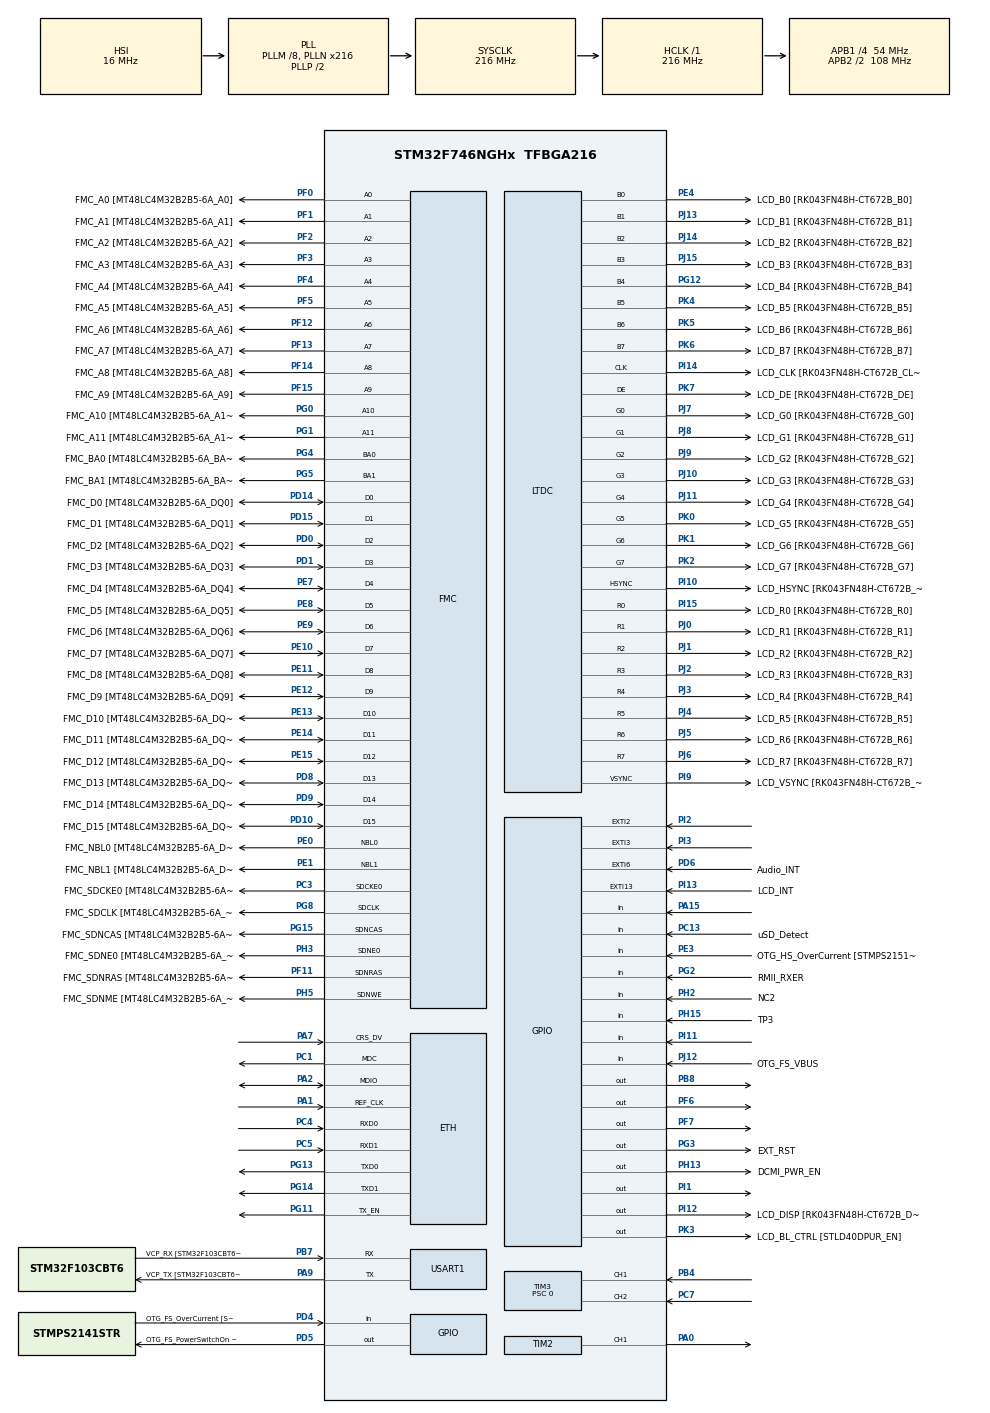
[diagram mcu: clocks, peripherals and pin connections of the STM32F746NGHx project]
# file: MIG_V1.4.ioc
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ETH.MediaInterface=HAL_ETH_RMII_MODE
FMC.CASLatency1=FMC_SDRAM_CAS_LATENCY_3
FMC.ExitSelfRefreshDelay1=7
FMC.LoadToActiveDelay1=4
FMC.RCDDelay1=3
FMC.RPDelay1=3
FMC.RPDelay2=3
FMC.ReadBurst1=FMC_SDRAM_RBURST_ENABLE
FMC.ReadBurst2=FMC_SDRAM_RBURST_ENABLE
FMC.RowCycleDelay1=7
FMC.RowCycleDelay2=7
FMC.SDClockPeriod1=FMC_SDRAM_CLOCK_PERIOD_2
FMC.SelfRefreshTime1=3
FMC.WriteRecoveryTime1=3
LWIP.BSP.number=1
LWIP.GATEWAY_ADDRESS=192.168.001.100
LWIP.IP_ADDRESS=172.024.001.001
LWIP.LWIP_DHCP=0
LWIP.LWIP_HTTPD=1
LWIP.LWIP_HTTPD_MAX_CGI_PARAMETERS=30
LWIP.LWIP_HTTPD_MAX_REQUEST_URI_LEN=500
LWIP.LWIP_HTTPD_POST_MAX_RESPONSE_URI_LEN=500
LWIP.LWIP_HTTPD_SSI_INCLUDE_TAG=0
LWIP.NETMASK_ADDRESS=255.255.000.000
LWIP.Version=v2.1.2_Cube
LWIP0.BSP.STBoard=false
LWIP0.BSP.api=BSP_COMPONENT_DRIVER
LWIP0.BSP.component=LAN8742
LWIP0.BSP.instance=LAN8742
LWIP0.BSP.name=Driver_PHY
LWIP0.BSP.semaphore=S_LAN8742
LWIP0.BSP.solution=LAN8742
Mcu.Family=STM32F7
Mcu.Name=STM32F746NGHx
Mcu.Package=TFBGA216
NVIC.PriorityGroup=NVIC_PRIORITYGROUP_4
NVIC.TIM3_IRQn=true\:0\:0\:false\:false\:true\:true\:true\:true
PA0/WKUP.Signal=S_TIM2_CH1_ETR
PA1.GPIO_Mode=GPIO_MODE_AF_PP
PA1.GPIO_PuPd=GPIO_NOPULL
PA1.GPIO_Speed=GPIO_SPEED_FREQ_VERY_HIGH
PA1.Mode=RMII
PA1.Signal=ETH_REF_CLK
PA10.GPIO_Label=OTG_FS_ID
PA10.Signal=USB_OTG_FS_ID
PA11.GPIO_Label=OTG_FS_N
PA11.Signal=USB_OTG_FS_DM
PA12.GPIO_Label=OTG_FS_P
PA12.Signal=USB_OTG_FS_DP
PA13.GPIO_Label=SWDIO
PA13.Signal=SYS_JTMS-SWDIO
PA14.GPIO_Label=SWCLK
PA14.Signal=SYS_JTCK-SWCLK
PA15.GPIO_PuPd=GPIO_PULLUP
PA15.Signal=GPIO_Input
PA2.GPIO_Mode=GPIO_MODE_AF_PP
PA2.GPIO_PuPd=GPIO_NOPULL
PA2.GPIO_Speed=GPIO_SPEED_FREQ_VERY_HIGH
PA2.Mode=RMII
PA2.Signal=ETH_MDIO
PA3.GPIO_Label=ULPI_D0 [USB3320C-EZK_D0]
PA3.Signal=USB_OTG_HS_ULPI_D0
PA4.GPIO_Label=DCMI_HSYNC
PA4.Signal=DCMI_HSYNC
PA5.GPIO_Label=ULPI_CLK [USB3320C-EZK_CLKOUT]
PA5.Signal=USB_OTG_HS_ULPI_CK
PA6.Signal=DCMI_PIXCLK
PA7.GPIO_Mode=GPIO_MODE_AF_PP
PA7.GPIO_PuPd=GPIO_NOPULL
PA7.GPIO_Speed=GPIO_SPEED_FREQ_VERY_HIGH
PA7.Mode=RMII
PA7.Signal=ETH_CRS_DV
PA9.GPIO_Label=VCP_TX [STM32F103CBT6_PA3]
PA9.GPIO_Mode=GPIO_MODE_AF_PP
PA9.GPIO_PuPd=GPIO_NOPULL
PA9.GPIO_Speed=GPIO_SPEED_FREQ_LOW
PA9.Mode=Asynchronous
PA9.Signal=USART1_TX
PB0.GPIO_Label=ULPI_D1 [USB3320C-EZK_D1]
PB0.Signal=USB_OTG_HS_ULPI_D1
PB1.GPIO_Label=ULPI_D2 [USB3320C-EZK_D2]
PB1.Signal=USB_OTG_HS_ULPI_D2
PB10.GPIO_Label=ULPI_D3 [USB3320C-EZK_D3]
PB10.Signal=USB_OTG_HS_ULPI_D3
PB11.GPIO_Label=ULPI_D4 [USB3320C-EZK_D4]
PB11.Signal=USB_OTG_HS_ULPI_D4
PB12.GPIO_Label=ULPI_D5 [USB3320C-EZK_D5]
PB12.Signal=USB_OTG_HS_ULPI_D5
PB13.GPIO_Label=ULPI_D6 [USB3320C-EZK_D6]
PB13.Signal=USB_OTG_HS_ULPI_D6
PB2.Signal=QUADSPI_CLK
PB3.GPIO_Label=SWO
PB3.Signal=SYS_JTDO-SWO
PB4.Signal=S_TIM3_CH1
PB5.GPIO_Label=ULPI_D7 [USB3320C-EZK_D7]
PB5.Signal=USB_OTG_HS_ULPI_D7
PB6.GPIO_Label=QSPI_NCS [N25Q128A13EF840E_S]
PB6.Signal=QUADSPI_BK1_NCS
PB7.GPIO_Label=VCP_RX [STM32F103CBT6_PA2]
PB7.GPIO_Mode=GPIO_MODE_AF_PP
PB7.GPIO_PuPd=GPIO_NOPULL
PB7.GPIO_Speed=GPIO_SPEED_FREQ_LOW
PB7.Mode=Asynchronous
PB7.Signal=USART1_RX
PB8.Signal=GPIO_Output
PC0.GPIO_Label=ULPI_STP [USB3320C-EZK_STP]
PC0.Signal=USB_OTG_HS_ULPI_STP
PC1.GPIO_Mode=GPIO_MODE_AF_PP
PC1.GPIO_PuPd=GPIO_NOPULL
PC1.GPIO_Speed=GPIO_SPEED_FREQ_VERY_HIGH
PC1.Mode=RMII
PC1.Signal=ETH_MDC
PC10.GPIO_Label=SDMMC_D2
PC10.Signal=SDMMC1_D2
PC11.GPIO_Label=SDMMC_D3
PC11.Signal=SDMMC1_D3
PC12.GPIO_Label=SDMMC_CK
PC12.Signal=SDMMC1_CK
PC13.GPIO_Label=uSD_Detect
PC13.Signal=GPIO_Input
PC14/OSC32_IN.GPIO_Label=RCC_OSC32_IN
PC14/OSC32_IN.Mode=LSE-External-Oscillator
PC14/OSC32_IN.Signal=RCC_OSC32_IN
PC15/OSC32_OUT.GPIO_Label=RCC_OSC32_OUT
PC15/OSC32_OUT.Mode=LSE-External-Oscillator
PC15/OSC32_OUT.Signal=RCC_OSC32_OUT
PC2.GPIO_Label=ULPI_DIR [USB3320C-EZK_DIR]
PC2.Signal=USB_OTG_HS_ULPI_DIR
PC3.GPIO_Label=FMC_SDCKE0 [MT48LC4M32B2B5-6A_CKE]
PC3.Mode=SdramChipSelect1_1
PC3.Signal=FMC_SDCKE0
PC4.GPIO_Mode=GPIO_MODE_AF_PP
PC4.GPIO_PuPd=GPIO_NOPULL
PC4.GPIO_Speed=GPIO_SPEED_FREQ_VERY_HIGH
PC4.Mode=RMII
PC4.Signal=ETH_RXD0
PC5.GPIO_Mode=GPIO_MODE_AF_PP
PC5.GPIO_PuPd=GPIO_NOPULL
PC5.GPIO_Speed=GPIO_SPEED_FREQ_VERY_HIGH
PC5.Mode=RMII
PC5.Signal=ETH_RXD1
PC7.Signal=S_TIM3_CH2
PC8.Signal=SDMMC1_D0
PC9.Signal=SDMMC1_D1
PD0.GPIO_Label=FMC_D2 [MT48LC4M32B2B5-6A_DQ2]
PD0.Signal=FMC_D2_DA2
PD1.GPIO_Label=FMC_D3 [MT48LC4M32B2B5-6A_DQ3]
PD1.Signal=FMC_D3_DA3
PD10.GPIO_Label=FMC_D15 [MT48LC4M32B2B5-6A_DQ15]
PD10.Signal=FMC_D15_DA15
PD11.GPIO_Label=QSPI_D0 [N25Q128A13EF840E_DQ0]
PD11.Signal=QUADSPI_BK1_IO0
PD12.GPIO_Label=QSPI_D1 [N25Q128A13EF840E_DQ1]
PD12.Signal=QUADSPI_BK1_IO1
PD13.GPIO_Label=QSPI_D3 [N25Q128A13EF840E_DQ3]
PD13.Signal=QUADSPI_BK1_IO3
PD14.GPIO_Label=FMC_D0 [MT48LC4M32B2B5-6A_DQ0]
PD14.Signal=FMC_D0_DA0
PD15.GPIO_Label=FMC_D1 [MT48LC4M32B2B5-6A_DQ1]
PD15.Signal=FMC_D1_DA1
PD2.GPIO_Label=SDMMC_D0
PD2.Signal=SDMMC1_CMD
PD3.GPIO_Label=DCMI_D5
PD3.Signal=DCMI_D5
PD4.GPIO_Label=OTG_FS_OverCurrent [STMPS2141STR_Fault]
PD4.Signal=GPIO_Input
PD5.GPIO_Label=OTG_FS_PowerSwitchOn [STMPS2141STR_EN]
PD5.PinState=GPIO_PIN_SET
PD5.Signal=GPIO_Output
PD6.GPIO_Label=Audio_INT
PD6.GPIO_ModeDefaultEXTI=GPIO_MODE_EVT_RISING
PD6.Signal=GPXTI6
PD7.GPIO_Label=SPDIF_RX0 [74LVC1G04SE_4]
PD7.Signal=SPDIFRX_IN0
PD8.GPIO_Label=FMC_D13 [MT48LC4M32B2B5-6A_DQ13]
PD8.Signal=FMC_D13_DA13
PD9.GPIO_Label=FMC_D14 [MT48LC4M32B2B5-6A_DQ14]
PD9.Signal=FMC_D14_DA14
PE0.GPIO_Label=FMC_NBL0 [MT48LC4M32B2B5-6A_DQM0]
PE0.Signal=FMC_NBL0
PE1.GPIO_Label=FMC_NBL1 [MT48LC4M32B2B5-6A_DQM1]
PE1.Signal=FMC_NBL1
PE10.GPIO_Label=FMC_D7 [MT48LC4M32B2B5-6A_DQ7]
PE10.Signal=FMC_D7_DA7
PE11.GPIO_Label=FMC_D8 [MT48LC4M32B2B5-6A_DQ8]
PE11.Signal=FMC_D8_DA8
PE12.GPIO_Label=FMC_D9 [MT48LC4M32B2B5-6A_DQ9]
PE12.Signal=FMC_D9_DA9
PE13.GPIO_Label=FMC_D10 [MT48LC4M32B2B5-6A_DQ10]
PE13.Signal=FMC_D10_DA10
PE14.GPIO_Label=FMC_D11 [MT48LC4M32B2B5-6A_DQ11]
PE14.Signal=FMC_D11_DA11
PE15.GPIO_Label=FMC_D12 [MT48LC4M32B2B5-6A_DQ12]
PE15.Signal=FMC_D12_DA12
PE2.GPIO_Label=QSPI_D2 [N25Q128A13EF840E_DQ2]
PE2.Signal=QUADSPI_BK1_IO2
PE3.GPIO_Label=OTG_HS_OverCurrent [STMPS2151STR_FAULT]
PE3.Signal=GPIO_Input
PE4.GPIO_Label=LCD_B0 [RK043FN48H-CT672B_B0]
PE4.Mode=RGB888
PE4.Signal=LTDC_B0
PE5.GPIO_Label=DCMI_D6
PE5.Signal=DCMI_D6
PE6.GPIO_Label=DCMI_D7
PE6.Signal=DCMI_D7
PE7.GPIO_Label=FMC_D4 [MT48LC4M32B2B5-6A_DQ4]
PE7.Signal=FMC_D4_DA4
PE8.GPIO_Label=FMC_D5 [MT48LC4M32B2B5-6A_DQ5]
PE8.Signal=FMC_D5_DA5
PE9.GPIO_Label=FMC_D6 [MT48LC4M32B2B5-6A_DQ6]
PE9.Signal=FMC_D6_DA6
PF0.GPIO_Label=FMC_A0 [MT48LC4M32B2B5-6A_A0]
PF0.Signal=FMC_A0
PF1.GPIO_Label=FMC_A1 [MT48LC4M32B2B5-6A_A1]
PF1.Signal=FMC_A1
PF11.GPIO_Label=FMC_SDNRAS [MT48LC4M32B2B5-6A_RAS]
PF11.Signal=FMC_SDNRAS
PF12.GPIO_Label=FMC_A6 [MT48LC4M32B2B5-6A_A6]
PF12.Signal=FMC_A6
PF13.GPIO_Label=FMC_A7 [MT48LC4M32B2B5-6A_A7]
PF13.Signal=FMC_A7
PF14.GPIO_Label=FMC_A8 [MT48LC4M32B2B5-6A_A8]
PF14.Signal=FMC_A8
PF15.GPIO_Label=FMC_A9 [MT48LC4M32B2B5-6A_A9]
PF15.Signal=FMC_A9
PF2.GPIO_Label=FMC_A2 [MT48LC4M32B2B5-6A_A2]
PF2.Signal=FMC_A2
PF3.GPIO_Label=FMC_A3 [MT48LC4M32B2B5-6A_A3]
PF3.Signal=FMC_A3
PF4.GPIO_Label=FMC_A4 [MT48LC4M32B2B5-6A_A4]
PF4.Signal=FMC_A4
PF5.GPIO_Label=FMC_A5 [MT48LC4M32B2B5-6A_A5]
PF5.Signal=FMC_A5
PF6.Signal=GPIO_Output
PF7.Signal=GPIO_Output
PG0.GPIO_Label=FMC_A10 [MT48LC4M32B2B5-6A_A10]
PG0.Signal=FMC_A10
PG1.GPIO_Label=FMC_A11 [MT48LC4M32B2B5-6A_A11]
PG1.Signal=FMC_A11
PG10.GPIO_Label=SAI2_SDB [WM8994ECS/R_ADCDAT1]
PG10.Signal=SAI2_SD_B
PG11.GPIO_Mode=GPIO_MODE_AF_PP
PG11.GPIO_PuPd=GPIO_NOPULL
PG11.GPIO_Speed=GPIO_SPEED_FREQ_VERY_HIGH
PG11.Mode=RMII
PG11.Signal=ETH_TX_EN
PG12.GPIO_Label=LCD_B4 [RK043FN48H-CT672B_B4]
PG12.Mode=RGB888
PG12.Signal=LTDC_B4
PG13.GPIO_Mode=GPIO_MODE_AF_PP
PG13.GPIO_PuPd=GPIO_NOPULL
PG13.GPIO_Speed=GPIO_SPEED_FREQ_VERY_HIGH
PG13.Mode=RMII
PG13.Signal=ETH_TXD0
PG14.GPIO_Mode=GPIO_MODE_AF_PP
PG14.GPIO_PuPd=GPIO_NOPULL
PG14.GPIO_Speed=GPIO_SPEED_FREQ_VERY_HIGH
PG14.Mode=RMII
PG14.Signal=ETH_TXD1
PG15.GPIO_Label=FMC_SDNCAS [MT48LC4M32B2B5-6A_CAS]
PG15.Signal=FMC_SDNCAS
PG2.GPIO_Label=RMII_RXER
PG2.Signal=GPIO_Input
PG3.GPIO_Label=EXT_RST
PG3.Signal=GPIO_Output
PG4.GPIO_Label=FMC_BA0 [MT48LC4M32B2B5-6A_BA0]
PG4.Signal=FMC_A14_BA0
PG5.GPIO_Label=FMC_BA1 [MT48LC4M32B2B5-6A_BA1]
PG5.Signal=FMC_A15_BA1
PG8.GPIO_Label=FMC_SDCLK [MT48LC4M32B2B5-6A_CLK]
PG8.Signal=FMC_SDCLK
PG9.GPIO_Label=DCMI_VSYNC
PG9.Signal=DCMI_VSYNC
PH0/OSC_IN.GPIO_Label=OSC_25M [NZ2520SB-25.00M_OUT]
PH0/OSC_IN.Signal=RCC_OSC_IN
PH1/OSC_OUT.Signal=RCC_OSC_OUT
PH10.GPIO_Label=DCMI_D1
PH10.Signal=DCMI_D1
PH11.GPIO_Label=DCMI_D2
PH11.Signal=DCMI_D2
PH12.GPIO_Label=DCMI_D3
PH12.Signal=DCMI_D3
PH13.GPIO_Label=DCMI_PWR_EN
PH13.Signal=GPIO_Output
PH14.GPIO_Label=DCMI_D4
PH14.Signal=DCMI_D4
PH15.GPIO_Label=TP3
PH15.Signal=GPIO_Input
PH2.GPIO_Label=NC2
PH2.Signal=GPIO_Input
PH3.GPIO_Label=FMC_SDNE0 [MT48LC4M32B2B5-6A_CS]
PH3.Mode=SdramChipSelect1_1
PH3.Signal=FMC_SDNE0
PH4.GPIO_Label=ULPI_NXT [USB3320C-EZK_NXT]
PH4.Signal=USB_OTG_HS_ULPI_NXT
PH5.GPIO_Label=FMC_SDNME [MT48LC4M32B2B5-6A_WE]
PH5.Signal=FMC_SDNWE
PH7.GPIO_Label=LCD_SCL [RK043FN48H-CT672B_SCL]
PH7.Signal=I2C3_SCL
PH8.GPIO_Label=LCD_SDA [RK043FN48H-CT672B_SDA]
PH8.Signal=I2C3_SDA
PH9.GPIO_Label=DCMI_D0
PH9.Signal=DCMI_D0
PI1.Signal=GPIO_Output
PI10.GPIO_Label=LCD_HSYNC [RK043FN48H-CT672B_HSYNC]
PI10.Mode=RGB888
PI10.Signal=LTDC_HSYNC
PI11.GPIO_PuPd=GPIO_PULLUP
PI11.Signal=GPIO_Input
PI12.GPIO_Label=LCD_DISP [RK043FN48H-CT672B_DISP] 
PI12.Signal=GPIO_Output
PI13.GPIO_Label=LCD_INT
PI13.GPIO_ModeDefaultEXTI=GPIO_MODE_EVT_RISING
PI13.Signal=GPXTI13
PI14.GPIO_Label=LCD_CLK [RK043FN48H-CT672B_CLK]
PI14.Mode=RGB888
PI14.Signal=LTDC_CLK
PI15.GPIO_Label=LCD_R0 [RK043FN48H-CT672B_R0]
PI15.Mode=RGB888
PI15.Signal=LTDC_R0
PI2.Signal=GPXTI2
PI3.GPIO_ModeDefaultEXTI=GPIO_MODE_IT_RISING
PI3.Signal=GPXTI3
PI4.GPIO_Label=SAI2_MCLKA [WM8994ECS/R_MCLK1]
PI4.Signal=SAI2_MCLK_A
PI5.GPIO_Label=SAI2_SCKA [WM8994ECS/R_BCLK1]
PI5.Signal=SAI2_SCK_A
PI6.GPIO_Label=SAI2_SDA [WM8994ECS/R_DACDAT1]
PI6.Signal=SAI2_SD_A
PI7.GPIO_Label=SAI2_FSA [WM8994ECS/R_LRCLK1]
PI7.Signal=SAI2_FS_A
PI8.GPIO_Label=NC1 [TP2]
PI8.Signal=RTC_TS
PI9.GPIO_Label=LCD_VSYNC [RK043FN48H-CT672B_VSYNC]
PI9.Mode=RGB888
PI9.Signal=LTDC_VSYNC
PJ0.GPIO_Label=LCD_R1 [RK043FN48H-CT672B_R1]
PJ0.Mode=RGB888
PJ0.Signal=LTDC_R1
PJ1.GPIO_Label=LCD_R2 [RK043FN48H-CT672B_R2]
PJ1.Mode=RGB888
PJ1.Signal=LTDC_R2
PJ10.GPIO_Label=LCD_G3 [RK043FN48H-CT672B_G3]
PJ10.Mode=RGB888
PJ10.Signal=LTDC_G3
PJ11.GPIO_Label=LCD_G4 [RK043FN48H-CT672B_G4]
PJ11.Mode=RGB888
PJ11.Signal=LTDC_G4
PJ12.GPIO_Label=OTG_FS_VBUS
PJ12.Signal=GPIO_Input
PJ13.GPIO_Label=LCD_B1 [RK043FN48H-CT672B_B1]
PJ13.Mode=RGB888
PJ13.Signal=LTDC_B1
PJ14.GPIO_Label=LCD_B2 [RK043FN48H-CT672B_B2]
PJ14.Mode=RGB888
PJ14.Signal=LTDC_B2
PJ15.GPIO_Label=LCD_B3 [RK043FN48H-CT672B_B3]
PJ15.Mode=RGB888
PJ15.Signal=LTDC_B3
PJ2.GPIO_Label=LCD_R3 [RK043FN48H-CT672B_R3]
PJ2.Mode=RGB888
PJ2.Signal=LTDC_R3
PJ3.GPIO_Label=LCD_R4 [RK043FN48H-CT672B_R4]
PJ3.Mode=RGB888
PJ3.Signal=LTDC_R4
PJ4.GPIO_Label=LCD_R5 [RK043FN48H-CT672B_R5]
PJ4.Mode=RGB888
PJ4.Signal=LTDC_R5
PJ5.GPIO_Label=LCD_R6 [RK043FN48H-CT672B_R6]
PJ5.Mode=RGB888
PJ5.Signal=LTDC_R6
PJ6.GPIO_Label=LCD_R7 [RK043FN48H-CT672B_R7]
PJ6.Mode=RGB888
PJ6.Signal=LTDC_R7
PJ7.GPIO_Label=LCD_G0 [RK043FN48H-CT672B_G0]
PJ7.Mode=RGB888
PJ7.Signal=LTDC_G0
PJ8.GPIO_Label=LCD_G1 [RK043FN48H-CT672B_G1]
PJ8.Mode=RGB888
PJ8.Signal=LTDC_G1
PJ9.GPIO_Label=LCD_G2 [RK043FN48H-CT672B_G2]
PJ9.Mode=RGB888
PJ9.Signal=LTDC_G2
PK0.GPIO_Label=LCD_G5 [RK043FN48H-CT672B_G5]
PK0.Mode=RGB888
PK0.Signal=LTDC_G5
PK1.GPIO_Label=LCD_G6 [RK043FN48H-CT672B_G6]
PK1.Mode=RGB888
PK1.Signal=LTDC_G6
PK2.GPIO_Label=LCD_G7 [RK043FN48H-CT672B_G7]
PK2.Mode=RGB888
PK2.Signal=LTDC_G7
PK3.GPIO_Label=LCD_BL_CTRL [STLD40DPUR_EN]
PK3.Signal=GPIO_Output
PK4.GPIO_Label=LCD_B5 [RK043FN48H-CT672B_B5]
PK4.Mode=RGB888
PK4.Signal=LTDC_B5
PK5.GPIO_Label=LCD_B6 [RK043FN48H-CT672B_B6]
PK5.Mode=RGB888
PK5.Signal=LTDC_B6
PK6.GPIO_Label=LCD_B7 [RK043FN48H-CT672B_B7]
PK6.Mode=RGB888
PK6.Signal=LTDC_B7
PK7.GPIO_Label=LCD_DE [RK043FN48H-CT672B_DE]
PK7.Mode=RGB888
PK7.Signal=LTDC_DE
ProjectManager.HeapSize=0x200
ProjectManager.StackSize=0x400
ProjectManager.TargetToolchain=STM32CubeIDE
RCC.AHBFreq_Value=216000000
RCC.APB1CLKDivider=RCC_HCLK_DIV4
RCC.APB1Freq_Value=54000000
RCC.APB1TimFreq_Value=108000000
RCC.APB2CLKDivider=RCC_HCLK_DIV2
RCC.APB2Freq_Value=108000000
RCC.APB2TimFreq_Value=216000000
RCC.CortexFreq_Value=216000000
RCC.HCLKFreq_Value=216000000
RCC.HSE_VALUE=25000000
RCC.HSI_VALUE=16000000
RCC.PLLM=8
RCC.PLLN=216
RCC.PLLSAIN=50
RCC.PLLSourceVirtual=RCC_PLLSOURCE_HSI
RCC.SYSCLKFreq_VALUE=216000000
RCC.SYSCLKSource=RCC_SYSCLKSOURCE_PLLCLK
RCC.USBFreq_Value=216000000
RCC.VCOOutputFreq_Value=432000000
SH.FMC_A0.0=FMC_A0,12b-sda1
SH.FMC_A1.0=FMC_A1,12b-sda1
SH.FMC_A10.0=FMC_A10,12b-sda1
SH.FMC_A11.0=FMC_A11,12b-sda1
SH.FMC_A14_BA0.0=FMC_BA0,FourSdramBanks1
SH.FMC_A15_BA1.0=FMC_BA1,FourSdramBanks1
SH.FMC_A2.0=FMC_A2,12b-sda1
SH.FMC_A3.0=FMC_A3,12b-sda1
SH.FMC_A4.0=FMC_A4,12b-sda1
SH.FMC_A5.0=FMC_A5,12b-sda1
SH.FMC_A6.0=FMC_A6,12b-sda1
SH.FMC_A7.0=FMC_A7,12b-sda1
SH.FMC_A8.0=FMC_A8,12b-sda1
SH.FMC_A9.0=FMC_A9,12b-sda1
SH.FMC_D0_DA0.0=FMC_D0,sd-16b-d1
SH.FMC_D10_DA10.0=FMC_D10,sd-16b-d1
SH.FMC_D11_DA11.0=FMC_D11,sd-16b-d1
SH.FMC_D12_DA12.0=FMC_D12,sd-16b-d1
SH.FMC_D13_DA13.0=FMC_D13,sd-16b-d1
SH.FMC_D14_DA14.0=FMC_D14,sd-16b-d1
SH.FMC_D15_DA15.0=FMC_D15,sd-16b-d1
SH.FMC_D1_DA1.0=FMC_D1,sd-16b-d1
SH.FMC_D2_DA2.0=FMC_D2,sd-16b-d1
SH.FMC_D3_DA3.0=FMC_D3,sd-16b-d1
SH.FMC_D4_DA4.0=FMC_D4,sd-16b-d1
SH.FMC_D5_DA5.0=FMC_D5,sd-16b-d1
SH.FMC_D6_DA6.0=FMC_D6,sd-16b-d1
SH.FMC_D7_DA7.0=FMC_D7,sd-16b-d1
SH.FMC_D8_DA8.0=FMC_D8,sd-16b-d1
SH.FMC_D9_DA9.0=FMC_D9,sd-16b-d1
SH.FMC_NBL0.0=FMC_NBL0,Sd2ByteEnable1
SH.FMC_NBL1.0=FMC_NBL1,Sd2ByteEnable1
SH.FMC_SDCLK.0=FMC_SDCLK,12b-sda1
SH.FMC_SDNCAS.0=FMC_SDNCAS,12b-sda1
SH.FMC_SDNRAS.0=FMC_SDNRAS,12b-sda1
SH.FMC_SDNWE.0=FMC_SDNWE,12b-sda1
SH.S_TIM2_CH1_ETR.0=TIM2_CH1,PWM Generation1 CH1
SH.S_TIM3_CH1.0=TIM3_CH1,Encoder_Interface
SH.S_TIM3_CH2.0=TIM3_CH2,Encoder_Interface
TIM2.Channel-PWM\ Generation1\ CH1=TIM_CHANNEL_1
TIM3.Period=65535
TIM3.Prescaler=0
USART1.VirtualMode-Asynchronous=VM_ASYNC
VP_LWIP_VS_Enabled.Mode=Enabled
VP_TIM2_VS_ClockSourceINT.Mode=Internal
board=STM32F746G-DISCO

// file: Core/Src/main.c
/* USER CODE BEGIN Header */
/**`
 ******************************************************************************
 * @file           : main.c
 * @brief          : Main program body
 ******************************************************************************
 * @attention
 *
 * Copyright (c) 2022 STMicroelectronics.
 * All rights reserved.
 *
 * This software is licensed under terms that can be found in the LICENSE file
 * in the root directory of this software component.
 * If no LICENSE file comes with this software, it is provided AS-IS.
 *
 ******************************************************************************
 */
/* USER CODE END Header */
#include "main.h"
#include "ltdc.h"
#include "lwip.h"
#include "tim.h"
#include "usart.h"
#include "gpio.h"
#include "fmc.h"

/* USER CODE BEGIN Includes */
#include "../../lvgl/lvgl.h"
#include "../../lv_conf.h"
#include "../../hal_stm_lvgl/tft/tft.h"
#include "../../hal_stm_lvgl/touchpad/touchpad.h"
#include "../lwip/apps/httpd.h"

float value1=1.4;
float value2=118.0;
float value3 = 3.0;
float value4 = 1.1;
float value5= 22.9;
float value6 = 0.4;

float value11=2.4;
float value22=123.0;
float value33 = 2.0;
float value44 = 2.1;
float value55= 25.9;
float value66 = 0.5;

//#include "../../lv_examples.h"
/* USER CODE END Includes */

/* USER CODE BEGIN PTD */
  // This assumes you have an image called 'my_image'
//int count;
// Declare the TFT display object and other global variables

//FOR ADC AND INPUT CAPTURE

#define FLASH_SECTOR7_ADDRESS 0x080C0000 // Must be word-aligned (multiple of 4)
#define FLASH_MAX_ADDRESS     0x080FFFFF
#define FLASH_SECTOR           FLASH_SECTOR_7

extern bool BYPASS;

typedef struct {
    float Kp;
    float Ki;
    float Kd;
    float prev_error;
    float integral;
} PID_Controller;

PID_Controller pid = { .Kp = 1.5f, .Ki = 0.5f, .Kd = 0.1f };
float target_speed = 100.0f;

uint32_t brake_start_time = 0;
uint32_t brake_end_time = 0;
uint8_t brake_started = 0;
uint8_t brake_finished = 0;

float prev_duty_percent = 20.0f;

char rx_buffer[10];          // UART RX buffer
uint8_t rx_index = 0;

uint8_t rx_data;     // For receiving 1 byte
char buffer[100];

char buffer1[100];
char buffer2[100];

char buffer_tx[100];
//float duty_cycle = 0.0f;
/* USER CODE END PTD */

/* USER CODE BEGIN PD */
extern SDRAM_HandleTypeDef hsdram1;

/* USER CODE END PD */

/* USER CODE BEGIN PV */
//extern struct netif gnetif;
/* USER CODE END PV */

void SystemClock_Config(void);
/* USER CODE BEGIN PFP */

void Flash_Write_Data(void);
void Flash_Read_Data(void);
void Flash_Erase_Sector7(void);

//void lv_example_main_page(void);  //FOR MAIN PAGEE

void lv_example_dropdown_2(void);  //FOR SETTING PAGE

void lv_example_img_1(void); //FOR IMAGES

void lv_example_btn_1(void);  //FOR BUTTONS

void lv_example_main_page(float value1,float value2,float value3,float value4,float value5,float value6);
void handle_two_t_screen(void);

float Get_Encoder_Speed(void); // Simulated for now
float PID_Compute(PID_Controller *pid, float setpoint, float measured, float dt);
void Set_PWM_Output(float duty);
void uart_code_for_dc_motor(void);
//void handle_2T_mode(float value11 , float value22, float value33 , float value44 , float value55, float value66);
/* USER CODE END PFP */

/* USER CODE BEGIN 0 */

//float target_voltage = 22.0f; // Set between 0 to 24
//
//void Set_PWM_Voltage(float voltage)
//{
//    if (voltage > 24.0f) voltage = 24.0f;
//    if (voltage < 0.0f) voltage = 0.0f;
//
//    float duty = (voltage / 24.0f) * 100.0f;
//    uint32_t pulse = (htim2.Init.Period + 1) * duty / 100.0f;
//    __HAL_TIM_SET_COMPARE(&htim2, TIM_CHANNEL_1, pulse);
//}

uint32_t encoder_position = 0;
int duty_percent = 50;  ///duty cycle in percentage

void Set_PWM_Duty(float duty)
{
    if (duty > 100.0f) duty = 100.0f;
    if (duty < 0.0f) duty = 0.0f;

    uint32_t pulse = (htim2.Init.Period + 1) * duty / 100.0f;
    __HAL_TIM_SET_COMPARE(&htim2, TIM_CHANNEL_1, pulse);
}

/* USER CODE END 0 */

int main(void)
{

  /* MCU Configuration--------------------------------------------------------*/

  /* Reset of all peripherals, Initializes the Flash interface and the Systick. */
  HAL_Init();

  /* Configure the system clock */
  SystemClock_Config();

  /* Initialize all configured peripherals */
  MX_GPIO_Init();
  MX_LTDC_Init();
  MX_USART1_UART_Init();
  MX_TIM2_Init();
  MX_FMC_Init();
  MX_LWIP_Init();
  MX_TIM3_Init();
  /* USER CODE BEGIN 2 */
	/* Enable I-Cache */
	//  ethernetif_notify_conn_changed(&gnetif);

	SDRAM_Initialization_Sequence(&hsdram1);

	SCB_EnableICache();

	/* Enable D-Cache */
	SCB_EnableDCache();
	MX_GPIO_Init();

//	Flash_Read_Data();

	lv_init();

	tft_init();

	touchpad_init();
//	uart_code_for_dc_motor();

//	lv_example_main_page();  //FOR MAIN PAGEE

	lv_example_dropdown_2();  //FOR SETTING PAGE

	lv_example_img_1(); //FOR IMAGES
    lvgl_encoder_init();
	lv_example_main_page(value1,value2,value3,value4,value5,value6);

    HAL_TIM_PWM_Start(&htim2, TIM_CHANNEL_1);
//    HAL_TIM_Base_Start(&htim3);

  /* USER CODE END 2 */

  /* Infinite loop */
  /* USER CODE BEGIN WHILE */
	while (1)
	{

			MX_LWIP_Process(); // To initiate the LWIP process
			Set_PWM_Duty(duty_percent);
			HAL_Delay(10);

//			Flash_Write_Data();

			lv_tick_inc(5);
			lv_task_handler();
//			uart_code_for_dc_motor();
			  if (HAL_GPIO_ReadPin(GPIOA, GPIO_PIN_15) == GPIO_PIN_RESET)
				{
				  HAL_GPIO_WritePin(GPIOI, GPIO_PIN_1, GPIO_PIN_SET);  // Turn on LED
				  HAL_Delay(50);
				}
				else
				{
				  HAL_GPIO_WritePin(GPIOI, GPIO_PIN_1, GPIO_PIN_RESET);  // Turn off LED
				  HAL_Delay(50);
				}
			  check_encoder_change();
			HAL_Delay(5);  // Small delay to prevent CPU overuse
		}
}

    /* USER CODE END WHILE */

    /* USER CODE BEGIN 3 */
	void HAL_GPIO_EXTI_Callback(uint16_t GPIO_Pin)
	{

		    if (GPIO_Pin == GPIO_PIN_3)  // A (CLK) pin on PI1
		    {
		        if (HAL_GPIO_ReadPin(GPIOI, GPIO_PIN_2) == GPIO_PIN_SET)
		        {
		            encoder_position++;  // Clockwise
		        }
		        else
		        {
		            encoder_position--;  // Counter-clockwise
		        }
		    }
	}

void uart_code_for_dc_motor(void)
{
	uint8_t receivedChar[2];
	HAL_UART_Receive(&huart1, &receivedChar, 1, HAL_MAX_DELAY);
	duty_percent = receivedChar[0] - '0';

        sprintf(buffer_tx, "uart cycle : %d \r\n", duty_percent);
        HAL_UART_Transmit(&huart1, (uint8_t *)buffer_tx, strlen(buffer_tx), HAL_MAX_DELAY);

//
		  if (duty_percent < 10.0f && brake_started == 0 && brake_finished == 0)
		        {
		            brake_start_time = __HAL_TIM_GET_COUNTER(&htim3);
		            brake_started = 1;
		            sprintf(buffer, "Brake start time: %d ms\r\n", brake_start_time);
		                HAL_UART_Transmit(&huart1, (uint8_t *)buffer, strlen(buffer), HAL_MAX_DELAY);

		        }

		        // Step 2: duty reaches 0% → brake complete
		        if (brake_started && duty_percent == 0.0f && brake_finished == 0)
		        {
		            brake_end_time = __HAL_TIM_GET_COUNTER(&htim3);
		            uint32_t brake_time = brake_end_time - brake_start_time;

		            sprintf(buffer1, "Brake endtime: %d ms\r\n", brake_end_time);
		                HAL_UART_Transmit(&huart1, (uint8_t *)buffer1, strlen(buffer1), HAL_MAX_DELAY);

		                sprintf(buffer2, "Brake time: %d ms\r\n", brake_time);
		         			                HAL_UART_Transmit(&huart1, (uint8_t *)buffer2, strlen(buffer2), HAL_MAX_DELAY);

		            brake_finished = 1;
		            brake_started = 0;
		        }

		        // Optional: reset state when motor is restarted
		        if (duty_percent > 10.0f)
		        {
		            brake_started = 0;
		            brake_finished = 0;
		        }
  /* USER CODE END 3 */
}

void SystemClock_Config(void)
{
  RCC_OscInitTypeDef RCC_OscInitStruct = {0};
  RCC_ClkInitTypeDef RCC_ClkInitStruct = {0};

  /** Configure LSE Drive Capability
  */
  HAL_PWR_EnableBkUpAccess();

  /** Configure the main internal regulator output voltage
  */
  __HAL_RCC_PWR_CLK_ENABLE();
  __HAL_PWR_VOLTAGESCALING_CONFIG(PWR_REGULATOR_VOLTAGE_SCALE1);

  /** Initializes the RCC Oscillators according to the specified parameters
  * in the RCC_OscInitTypeDef structure.
  */
  RCC_OscInitStruct.OscillatorType = RCC_OSCILLATORTYPE_HSI;
  RCC_OscInitStruct.HSIState = RCC_HSI_ON;
  RCC_OscInitStruct.HSICalibrationValue = RCC_HSICALIBRATION_DEFAULT;
  RCC_OscInitStruct.PLL.PLLState = RCC_PLL_ON;
  RCC_OscInitStruct.PLL.PLLSource = RCC_PLLSOURCE_HSI;
  RCC_OscInitStruct.PLL.PLLM = 8;
  RCC_OscInitStruct.PLL.PLLN = 216;
  RCC_OscInitStruct.PLL.PLLP = RCC_PLLP_DIV2;
  RCC_OscInitStruct.PLL.PLLQ = 2;
  if (HAL_RCC_OscConfig(&RCC_OscInitStruct) != HAL_OK)
  {
    Error_Handler();
  }

  /** Activate the Over-Drive mode
  */
  if (HAL_PWREx_EnableOverDrive() != HAL_OK)
  {
    Error_Handler();
  }

  /** Initializes the CPU, AHB and APB buses clocks
  */
  RCC_ClkInitStruct.ClockType = RCC_CLOCKTYPE_HCLK|RCC_CLOCKTYPE_SYSCLK
                              |RCC_CLOCKTYPE_PCLK1|RCC_CLOCKTYPE_PCLK2;
  RCC_ClkInitStruct.SYSCLKSource = RCC_SYSCLKSOURCE_PLLCLK;
  RCC_ClkInitStruct.AHBCLKDivider = RCC_SYSCLK_DIV1;
  RCC_ClkInitStruct.APB1CLKDivider = RCC_HCLK_DIV4;
  RCC_ClkInitStruct.APB2CLKDivider = RCC_HCLK_DIV2;

  if (HAL_RCC_ClockConfig(&RCC_ClkInitStruct, FLASH_LATENCY_7) != HAL_OK)
  {
    Error_Handler();
  }
}

void Error_Handler(void)
{
	__disable_irq();
	while (1)
	{
	}
}
